AUTOSAR XML (schema 4-3-0)
package /PEPS/ComponentTypes_PEPS
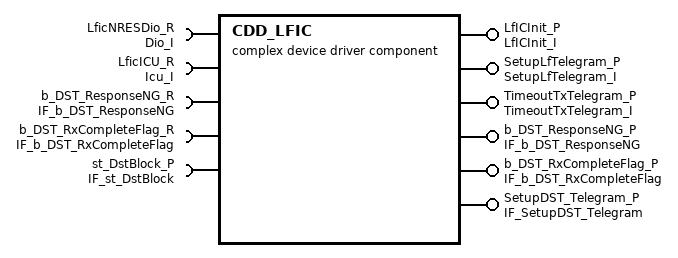
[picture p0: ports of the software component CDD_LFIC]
  complex device driver sw component type CDD_LFIC
    provide port LfICInit_P: server-com-spec{operation=CS, queue-length=1}, provided-interface=LfICInit_I
    provide port SetupLfTelegram_P: server-com-spec{operation=CS, queue-length=1}, provided-interface=SetupLfTelegram_I
    provide port TimeoutTxTelegram_P: server-com-spec{operation=CS, queue-length=1}, provided-interface=TimeoutTxTelegram_I
    require port LficNRESDio_R: required-com-specs=[Write, Read], required-interface=Dio_I
    require port LficICU_R: required-com-specs=[IcuEnableEdgeDetection, IcuEnableNotification, IcuDisableNotification, IcuDisableEdgeDetection], required-interface=Icu_I
    provide port b_DST_ResponseNG_P: nonqueued-sender-com-spec{data-element=SR, init-value=0}, provided-interface=IF_b_DST_ResponseNG
    require port b_DST_ResponseNG_R: nonqueued-receiver-com-spec{data-element=SR, filter=data-filter-type=ALWAYS, init-value=0}, required-interface=IF_b_DST_ResponseNG
    provide port b_DST_RxCompleteFlag_P: nonqueued-sender-com-spec{data-element=SR, init-value=0}, provided-interface=IF_b_DST_RxCompleteFlag
    require port b_DST_RxCompleteFlag_R: nonqueued-receiver-com-spec{data-element=SR, filter=data-filter-type=ALWAYS, init-value=0}, required-interface=IF_b_DST_RxCompleteFlag
    require port st_DstBlock_P: required-interface=IF_st_DstBlock
      required-com-specs:
        data-element=security_key_number, filter=data-filter-type=ALWAYS, init-value=[0]
        data-element=write_fob_number, filter=data-filter-type=ALWAYS, init-value=0
        data-element=encryption, filter=data-filter-type=ALWAYS, init-value=[0]
        data-element=challenge, filter=data-filter-type=ALWAYS, init-value=[0]
        data-element=vehicle_serial, filter=data-filter-type=ALWAYS, init-value=[0]
    provide port SetupDST_Telegram_P: server-com-spec{operation=CS, queue-length=1}, provided-interface=IF_SetupDST_Telegram
    behavior CDD_LFIC_InternalBehavior
      4 x operation invoked event:
        OIE_RE_LFIC_Init_LficInit_P_CS: start-on-event=RE_LFIC_Init, operation=LfICInit_P.CS
        OIE_RE_SetupLF_Telegram_SetupLFTelegram_P_CS: start-on-event=RE_SetupLF_Telegram, operation=SetupLfTelegram_P.CS
        OIE_RE_Timeout_Tx_Telegram_TimeoutTxTelegram_P_CS: start-on-event=RE_Timeout_Tx_Telegram, operation=TimeoutTxTelegram_P.CS
        OIT_RE_SetupDST_Telegram_SetupDST_Telegram_P_CS: start-on-event=RE_SetupDST_Telegram, operation=SetupDST_Telegram_P.CS
      5 x runnable:
        RE_LFIC_Init
          6 x sync call:
            SC_LficICU_R_IcuEnableEdgeDetection: operation=LficICU_R.IcuEnableEdgeDetection
            SC_LficICU_R_IcuEnableNotification: operation=LficICU_R.IcuEnableNotification
            SC_LficNRESDio_R_Read: operation=LficNRESDio_R.Read
            SC_LficNRESDio_R_Write: operation=LficNRESDio_R.Write
            SC_LficICU_R_IcuDisableEdgeDetection: operation=LficICU_R.IcuDisableEdgeDetection
            SC_LficICU_R_IcuDisableNotification: operation=LficICU_R.IcuDisableNotification
        RE_SetupLF_Telegram
        RE_Timeout_Tx_Telegram
        RE_SetupDST_Telegram
          data-receive-point-by-arguments:
            5 x access:
              REC_st_DstBlock_P_challenge: accessed-variable=st_DstBlock_P.challenge
              REC_st_DstBlock_P_encryption: accessed-variable=st_DstBlock_P.encryption
              REC_st_DstBlock_P_security_key_number: accessed-variable=st_DstBlock_P.security_key_number
              REC_st_DstBlock_P_vehicle_serial: accessed-variable=st_DstBlock_P.vehicle_serial
              REC_st_DstBlock_P_write_fob_number: accessed-variable=st_DstBlock_P.write_fob_number
        RE_DST_RX_ISR
          data-send-points:
            access SEND_b_DST_ResponseNG_P_SR: accessed-variable=b_DST_ResponseNG_P.SR
            access SEND_b_DST_RxCompleteFlag_P_SR: accessed-variable=b_DST_RxCompleteFlag_P.SR
  swc implementation CDD_LFIC_Implementation: behavior=CDD_LFIC_InternalBehavior
    code-descriptors:
      code Default: artifact-descriptors=autosar-engineering-object=category=SWSRC
